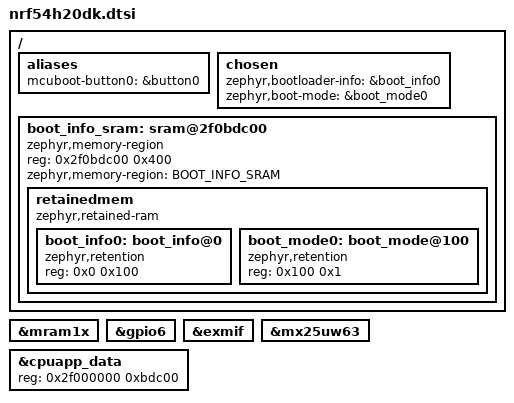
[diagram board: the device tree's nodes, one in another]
/* Delete Zephyr-default partitions before redefining them.
 * IronSide SE occupies 0x0-0x30000 and is not touched.
 */
&mram1x { /delete-node/ partitions; };

&gpio6 {
	status = "okay";
};

&exmif {
	status = "okay";
};

&mx25uw63 {
	status = "okay";
};

/ {
	aliases {
		mcuboot-button0 = &button0;
	};
};

#include "nrf54h20dk-partitions.dtsi"

/* Bootloader info shared-data area: the last KB of this board's RAM, kept
 * out of the managed RAM so neither image clobbers it. The bootloader
 * writes its boot state here on every boot (BOOT_SHARE_DATA_BOOTINFO ->
 * BLINFO TLVs via boot_write_shared_data()); the application reads the
 * same region to answer the SMP bootloader-info command (RETENTION_
 * BOOTLOADER_INFO_TYPE_MCUBOOT). Carved here because this dtsi applies to
 * both images.
 *
 * A second, one-byte retention cell in the same block backs the boot-mode
 * flag (zephyr,boot-mode): the application sets it to request the
 * bootloader's update mode (reset_to_bootloader() / RunMode.UF2) and the
 * bootloader reads and clears it at boot (io_detect_boot_mode()). SRAM
 * content survives the warm reset that follows the request, which is all a
 * button-less entrance needs; a power cycle simply drops the request.
 */
&cpuapp_data {
	reg = <0x2f000000 0xbdc00>;
};

/ {
	chosen {
		zephyr,bootloader-info = &boot_info0;
		zephyr,boot-mode = &boot_mode0;
	};

	boot_info_sram: sram@2f0bdc00 {
		compatible = "zephyr,memory-region", "mmio-sram";
		reg = <0x2f0bdc00 0x400>;
		zephyr,memory-region = "BOOT_INFO_SRAM";
		status = "okay";

		retainedmem {
			compatible = "zephyr,retained-ram";
			status = "okay";
			#address-cells = <1>;
			#size-cells = <1>;

			boot_info0: boot_info@0 {
				compatible = "zephyr,retention";
				status = "okay";
				reg = <0x0 0x100>;
			};

			boot_mode0: boot_mode@100 {
				compatible = "zephyr,retention";
				status = "okay";
				reg = <0x100 0x1>;
			};
		};
	};
};
